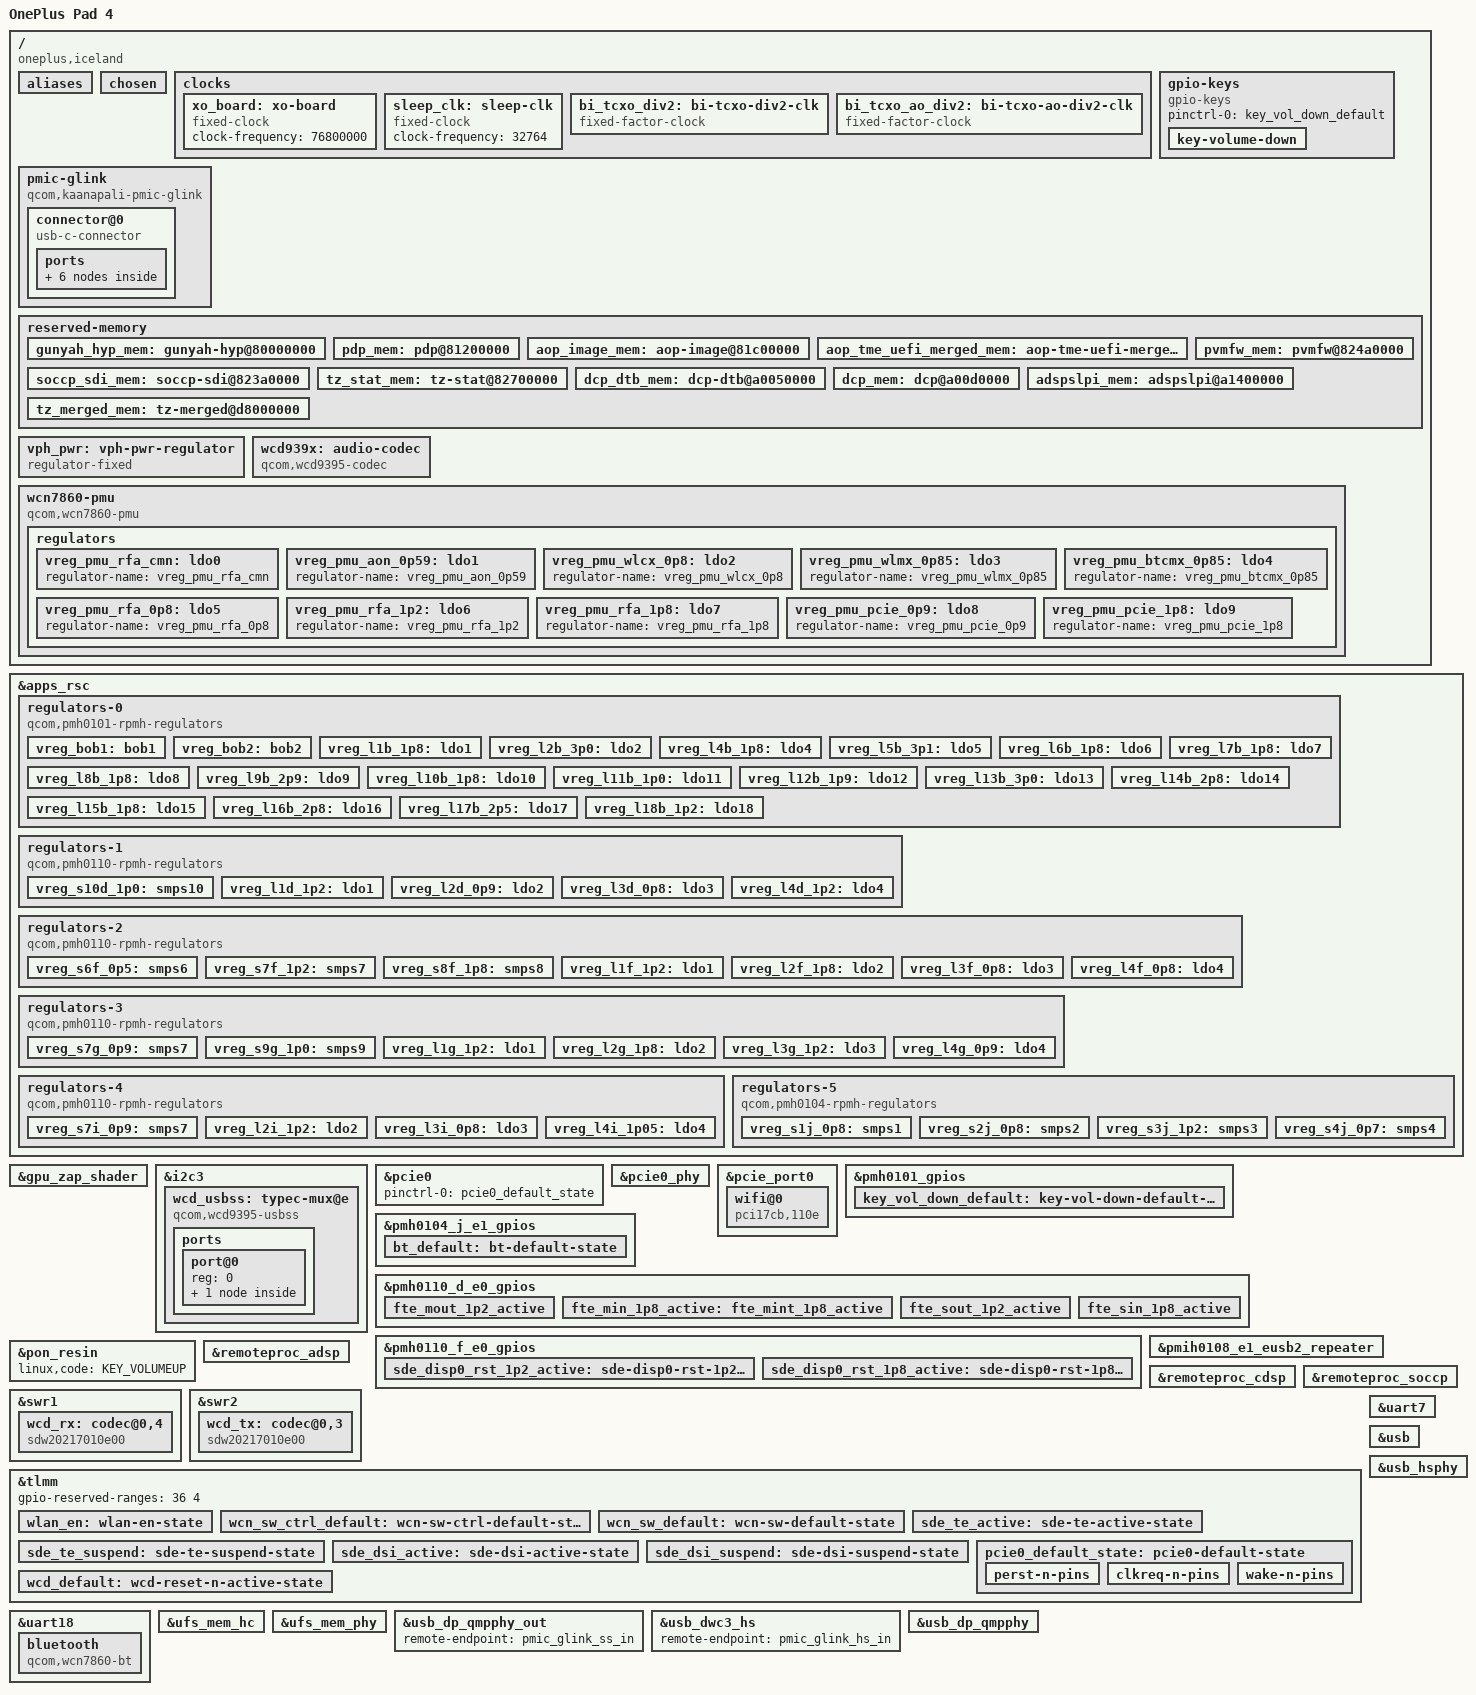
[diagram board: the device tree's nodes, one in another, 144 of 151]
// SPDX-License-Identifier: BSD-3-Clause
/*
 * Copyright (c) 2026, map220v <map220v300@gmail.com>
 */

/dts-v1/;

#include <dt-bindings/gpio/gpio.h>
#include <dt-bindings/input/linux-event-codes.h>
#include <dt-bindings/leds/common.h>
#include <dt-bindings/regulator/qcom,rpmh-regulator.h>
#include "kaanapali.dtsi"

#include "pmh0101.dtsi"              /* SPMI0: SID-1       */
#include "pmh0104-kaanapali.dtsi"    /* SPMI1: SID-9       */
#include "pmh0110-kaanapali.dtsi"    /* SPMI0: SID-3/5/6/8 */
#include "pmih0108-kaanapali.dtsi"   /* SPMI1: SID-7       */
#include "pmk8850.dtsi"              /* SPMI0: SID-0       */

/delete-node/ &pdp_mem;
/delete-node/ &adspslpi_mem;

/* SM8850P doesn't have Modem DSP */
/delete-node/ &dsm_partition_1_mem;
/delete-node/ &dsm_partition_2_mem;
/delete-node/ &mpss_mem;
/delete-node/ &q6_mpss_dtb_mem;
/delete-node/ &rmtfs_mem;

/ {
	model = "OnePlus Pad 4";
	compatible = "oneplus,iceland", "qcom,kaanapali";
	chassis-type = "tablet";

	aliases {
		serial0 = &uart7;
		serial1 = &uart18;
	};

	chosen { };

	clocks {
		xo_board: xo-board {
			compatible = "fixed-clock";
			clock-frequency = <76800000>;
			#clock-cells = <0>;
		};

		sleep_clk: sleep-clk {
			compatible = "fixed-clock";
			clock-frequency = <32764>;
			#clock-cells = <0>;
		};

		bi_tcxo_div2: bi-tcxo-div2-clk {
			compatible = "fixed-factor-clock";
			#clock-cells = <0>;

			clocks = <&rpmhcc RPMH_CXO_CLK>;
			clock-mult = <1>;
			clock-div = <2>;
		};

		bi_tcxo_ao_div2: bi-tcxo-ao-div2-clk {
			compatible = "fixed-factor-clock";
			#clock-cells = <0>;

			clocks = <&rpmhcc RPMH_CXO_CLK_A>;
			clock-mult = <1>;
			clock-div = <2>;
		};
	};

	gpio-keys {
		compatible = "gpio-keys";

		pinctrl-0 = <&key_vol_down_default>;
		pinctrl-names = "default";

		key-volume-down {
			label = "Volume Down";
			linux,code = <KEY_VOLUMEDOWN>;
			gpios = <&pmh0101_gpios 6 GPIO_ACTIVE_LOW>;
			debounce-interval = <32>;
			linux,can-disable;
			wakeup-source;
		};
	};

	pmic-glink {
		compatible = "qcom,kaanapali-pmic-glink";
		#address-cells = <1>;
		#size-cells = <0>;

		connector@0 {
			compatible = "usb-c-connector";
			reg = <0>;

			power-role = "dual";
			data-role = "dual";

			ports {
				#address-cells = <1>;
				#size-cells = <0>;

				port@0 {
					reg = <0>;

					pmic_glink_hs_in: endpoint {
						remote-endpoint = <&usb_dwc3_hs>;
					};
				};

				port@1 {
					reg = <1>;

					pmic_glink_ss_in: endpoint {
						remote-endpoint = <&usb_dp_qmpphy_out>;
					};
				};

				port@2 {
					reg = <2>;

					pmic_glink_sbu: endpoint {
						remote-endpoint = <&wcd_usbss_sbu_mux>;
					};
				};
			};
		};
	};

	reserved-memory {
		gunyah_hyp_mem: gunyah-hyp@80000000 {
			reg = <0x0 0x80000000 0x0 0xe00000>;
			no-map;
		};

		pdp_mem: pdp@81200000 {
			reg = <0x0 0x81200000 0x0 0x200000>;
			no-map;
		};

		aop_image_mem: aop-image@81c00000 {
			reg = <0x0 0x81c00000 0x0 0x60000>;
			no-map;
		};

		/* Merged aop_config, tme_crash_dump, tme_log and uefi_log regions */
		aop_tme_uefi_merged_mem: aop-tme-uefi-merged@81c80000 {
			reg = <0x0 0x81c80000 0x0 0x74000>;
			no-map;
		};

		soccp_sdi_mem: soccp-sdi@823a0000 {
			reg = <0x0 0x823a0000 0x0 0x40000>;
			no-map;
		};

		pvmfw_mem: pvmfw@824a0000 {
			reg = <0x0 0x824a0000 0x0 0x100000>;
			no-map;
		};

		tz_stat_mem: tz-stat@82700000 {
			reg = <0x0 0x82700000 0x0 0x100000>;
			no-map;
		};

		dcp_dtb_mem: dcp-dtb@a0050000 {
			reg = <0x0 0xa0050000 0x0 0x80000>;
			no-map;
		};

		dcp_mem: dcp@a00d0000 {
			reg = <0x0 0xa00d0000 0x0 0x300000>;
			no-map;
		};

		adspslpi_mem: adspslpi@a1400000 {
			reg = <0x0 0xa1400000 0x0 0x5000000>;
			no-map;
		};

		/* Merged hyp_ac, tz_reserved, xbl_sc, tz_ac, and qtee regions */
		tz_merged_mem: tz-merged@d8000000 {
			reg = <0x0 0xd8000000 0x0 0x800000>;
			no-map;
		};
	};

	vph_pwr: vph-pwr-regulator {
		compatible = "regulator-fixed";

		regulator-name = "vph_pwr";
		regulator-min-microvolt = <3700000>;
		regulator-max-microvolt = <3700000>;

		regulator-always-on;
		regulator-boot-on;
	};

	wcd939x: audio-codec {
		compatible = "qcom,wcd9395-codec", "qcom,wcd9390-codec";

		pinctrl-0 = <&wcd_default>;
		pinctrl-names = "default";

		qcom,micbias1-microvolt = <2700000>;
		qcom,micbias2-microvolt = <1800000>;
		qcom,micbias3-microvolt = <1800000>;
		qcom,micbias4-microvolt = <1800000>;
		qcom,mbhc-buttons-vthreshold-microvolt = <75000 150000 237000 500000
							  500000 500000 500000 500000>;
		qcom,mbhc-headset-vthreshold-microvolt = <1700000>;
		qcom,mbhc-headphone-vthreshold-microvolt = <50000>;
		qcom,rx-device = <&wcd_rx>;
		qcom,tx-device = <&wcd_tx>;

		reset-gpios = <&tlmm 161 GPIO_ACTIVE_LOW>;

		vdd-buck-supply = <&vreg_l15b_1p8>;
		vdd-rxtx-supply = <&vreg_l15b_1p8>;
		vdd-io-supply = <&vreg_l15b_1p8>;
		vdd-mic-bias-supply = <&vreg_bob1>;
		vdd-px-supply = <&vreg_l1g_1p2>;

		#sound-dai-cells = <1>;
	};

	wcn7860-pmu {
		compatible = "qcom,wcn7860-pmu";

		pinctrl-names = "default";
		pinctrl-0 = <&wlan_en>, <&bt_default>;

		wlan-enable-gpios = <&tlmm 16 GPIO_ACTIVE_HIGH>;
		bt-enable-gpios = <&pmh0104_j_e1_gpios 5 GPIO_ACTIVE_HIGH>;

		vddio-supply = <&vreg_l2g_1p8>;
		vddio1p2-supply = <&vreg_l3g_1p2>;
		vddaon-supply = <&vreg_s1j_0p8>;
		vdddig-supply = <&vreg_s2j_0p8>;
		vddrfa1p2-supply = <&vreg_s7f_1p2>;
		vddrfa1p8-supply = <&vreg_s8f_1p8>;

		clocks = <&rpmhcc RPMH_RF_CLK1>;

		regulators {
			vreg_pmu_rfa_cmn: ldo0 {
				regulator-name = "vreg_pmu_rfa_cmn";
			};

			vreg_pmu_aon_0p59: ldo1 {
				regulator-name = "vreg_pmu_aon_0p59";
			};

			vreg_pmu_wlcx_0p8: ldo2 {
				regulator-name = "vreg_pmu_wlcx_0p8";
			};

			vreg_pmu_wlmx_0p85: ldo3 {
				regulator-name = "vreg_pmu_wlmx_0p85";
			};

			vreg_pmu_btcmx_0p85: ldo4 {
				regulator-name = "vreg_pmu_btcmx_0p85";
			};

			vreg_pmu_rfa_0p8: ldo5 {
				regulator-name = "vreg_pmu_rfa_0p8";
			};

			vreg_pmu_rfa_1p2: ldo6 {
				regulator-name = "vreg_pmu_rfa_1p2";
			};

			vreg_pmu_rfa_1p8: ldo7 {
				regulator-name = "vreg_pmu_rfa_1p8";
			};

			vreg_pmu_pcie_0p9: ldo8 {
				regulator-name = "vreg_pmu_pcie_0p9";
			};

			vreg_pmu_pcie_1p8: ldo9 {
				regulator-name = "vreg_pmu_pcie_1p8";
			};
		};
	};
};

&apps_rsc {
	regulators-0 {
		compatible = "qcom,pmh0101-rpmh-regulators";
		qcom,pmic-id = "B_E0";

		vdd-bob1-supply = <&vph_pwr>;
		vdd-bob2-supply = <&vph_pwr>;
		vdd-l1-l4-l10-supply = <&vreg_s8f_1p8>;
		vdd-l2-l13-l14-supply = <&vreg_bob1>;
		vdd-l3-l11-supply = <&vreg_s7f_1p2>;
		vdd-l5-l16-supply = <&vreg_bob1>;
		vdd-l6-l7-supply = <&vreg_bob1>;
		vdd-l8-l9-supply = <&vreg_bob1>;
		vdd-l12-supply = <&vreg_s8f_1p8>;
		vdd-l15-supply = <&vreg_s8f_1p8>;
		vdd-l17-supply = <&vreg_bob2>;
		vdd-l18-supply = <&vreg_s7f_1p2>;

		vreg_bob1: bob1 {
			regulator-name = "vreg_bob1";
			regulator-min-microvolt = <3008000>;
			regulator-max-microvolt = <4000000>;
			regulator-initial-mode = <RPMH_REGULATOR_MODE_HPM>;
		};

		vreg_bob2: bob2 {
			regulator-name = "vreg_bob2";
			regulator-min-microvolt = <2704000>;
			regulator-max-microvolt = <3552000>;
			regulator-initial-mode = <RPMH_REGULATOR_MODE_HPM>;
		};

		vreg_l1b_1p8: ldo1 {
			regulator-name = "vreg_l1b_1p8";
			regulator-min-microvolt = <1800000>;
			regulator-max-microvolt = <1800000>;
			regulator-initial-mode = <RPMH_REGULATOR_MODE_AUTO>;
			regulator-allow-set-load;
			regulator-allowed-modes = <RPMH_REGULATOR_MODE_LPM
						   RPMH_REGULATOR_MODE_AUTO>;
		};

		vreg_l2b_3p0: ldo2 {
			regulator-name = "vreg_l2b_3p0";
			regulator-min-microvolt = <3008000>;
			regulator-max-microvolt = <3048000>;
			regulator-initial-mode = <RPMH_REGULATOR_MODE_AUTO>;
			regulator-allow-set-load;
			regulator-allowed-modes = <RPMH_REGULATOR_MODE_LPM
						   RPMH_REGULATOR_MODE_AUTO>;
		};

		vreg_l4b_1p8: ldo4 {
			regulator-name = "vreg_l4b_1p8";
			regulator-min-microvolt = <1800000>;
			regulator-max-microvolt = <1800000>;
			regulator-initial-mode = <RPMH_REGULATOR_MODE_AUTO>;
			regulator-allow-set-load;
			regulator-allowed-modes = <RPMH_REGULATOR_MODE_LPM
						   RPMH_REGULATOR_MODE_AUTO>;
		};

		vreg_l5b_3p1: ldo5 {
			regulator-name = "vreg_l5b_3p1";
			regulator-min-microvolt = <3100000>;
			regulator-max-microvolt = <3148000>;
			regulator-initial-mode = <RPMH_REGULATOR_MODE_AUTO>;
			regulator-allow-set-load;
			regulator-allowed-modes = <RPMH_REGULATOR_MODE_LPM
						   RPMH_REGULATOR_MODE_AUTO>;
		};

		vreg_l6b_1p8: ldo6 {
			regulator-name = "vreg_l6b_1p8";
			regulator-min-microvolt = <1800000>;
			regulator-max-microvolt = <3008000>;
			regulator-initial-mode = <RPMH_REGULATOR_MODE_AUTO>;
			regulator-allow-set-load;
			regulator-allowed-modes = <RPMH_REGULATOR_MODE_LPM
						   RPMH_REGULATOR_MODE_AUTO>;
		};

		vreg_l7b_1p8: ldo7 {
			regulator-name = "vreg_l7b_1p8";
			regulator-min-microvolt = <1800000>;
			regulator-max-microvolt = <3008000>;
			regulator-initial-mode = <RPMH_REGULATOR_MODE_AUTO>;
			regulator-allow-set-load;
			regulator-allowed-modes = <RPMH_REGULATOR_MODE_LPM
						   RPMH_REGULATOR_MODE_AUTO>;
		};

		vreg_l8b_1p8: ldo8 {
			regulator-name = "vreg_l8b_1p8";
			regulator-min-microvolt = <1800000>;
			regulator-max-microvolt = <3008000>;
			regulator-initial-mode = <RPMH_REGULATOR_MODE_AUTO>;
			regulator-allow-set-load;
			regulator-allowed-modes = <RPMH_REGULATOR_MODE_LPM
						   RPMH_REGULATOR_MODE_AUTO>;
		};

		vreg_l9b_2p9: ldo9 {
			regulator-name = "vreg_l9b_2p9";
			regulator-min-microvolt = <2960000>;
			regulator-max-microvolt = <3008000>;
			regulator-initial-mode = <RPMH_REGULATOR_MODE_HPM>;
			regulator-allow-set-load;
			regulator-allowed-modes = <RPMH_REGULATOR_MODE_LPM
						   RPMH_REGULATOR_MODE_HPM>;
		};

		vreg_l10b_1p8: ldo10 {
			regulator-name = "vreg_l10b_1p8";
			regulator-min-microvolt = <1800000>;
			regulator-max-microvolt = <1800000>;
			regulator-initial-mode = <RPMH_REGULATOR_MODE_AUTO>;
			regulator-allow-set-load;
			regulator-allowed-modes = <RPMH_REGULATOR_MODE_LPM
						   RPMH_REGULATOR_MODE_AUTO>;
		};

		vreg_l11b_1p0: ldo11 {
			regulator-name = "vreg_l11b_1p0";
			regulator-min-microvolt = <1000000>;
			regulator-max-microvolt = <1292000>;
			regulator-initial-mode = <RPMH_REGULATOR_MODE_AUTO>;
			regulator-allow-set-load;
			regulator-allowed-modes = <RPMH_REGULATOR_MODE_LPM
						   RPMH_REGULATOR_MODE_AUTO>;
		};

		/* OEM change for Display */
		vreg_l12b_1p9: ldo12 {
			regulator-name = "vreg_l12b_1p9";
			regulator-min-microvolt = <1800000>;//OEM set to 1.2V, but it was too low
			regulator-max-microvolt = <1896000>;
			regulator-initial-mode = <RPMH_REGULATOR_MODE_AUTO>;
			regulator-allow-set-load;
			regulator-allowed-modes = <RPMH_REGULATOR_MODE_LPM
						   RPMH_REGULATOR_MODE_AUTO>;
		};

		vreg_l13b_3p0: ldo13 {
			regulator-name = "vreg_l13b_3p0";
			regulator-min-microvolt = <3000000>;
			regulator-max-microvolt = <3000000>;
			regulator-initial-mode = <RPMH_REGULATOR_MODE_AUTO>;
			regulator-allow-set-load;
			regulator-allowed-modes = <RPMH_REGULATOR_MODE_LPM
						   RPMH_REGULATOR_MODE_AUTO>;
		};

		/* OEM change for Camera */
		vreg_l14b_2p8: ldo14 {
			regulator-name = "vreg_l14b_2p8";
			regulator-min-microvolt = <2800000>;
			regulator-max-microvolt = <2800000>;
			regulator-initial-mode = <RPMH_REGULATOR_MODE_AUTO>;
			regulator-allow-set-load;
			regulator-allowed-modes = <RPMH_REGULATOR_MODE_LPM
						   RPMH_REGULATOR_MODE_AUTO>;
		};

		vreg_l15b_1p8: ldo15 {
			regulator-name = "vreg_l15b_1p8";
			regulator-min-microvolt = <1800000>;
			regulator-max-microvolt = <1800000>;
			regulator-initial-mode = <RPMH_REGULATOR_MODE_AUTO>;
			regulator-allow-set-load;
			regulator-allowed-modes = <RPMH_REGULATOR_MODE_LPM
						   RPMH_REGULATOR_MODE_AUTO>;
		};

		/* OEM change for Camera */
		vreg_l16b_2p8: ldo16 {
			regulator-name = "vreg_l16b_2p8";
			regulator-min-microvolt = <2800000>;
			regulator-max-microvolt = <2800000>;
			regulator-initial-mode = <RPMH_REGULATOR_MODE_AUTO>;
			regulator-allow-set-load;
			regulator-allowed-modes = <RPMH_REGULATOR_MODE_LPM
						   RPMH_REGULATOR_MODE_AUTO>;
		};

		vreg_l17b_2p5: ldo17 {
			regulator-name = "vreg_l17b_2p5";
			regulator-min-microvolt = <2504000>;
			regulator-max-microvolt = <2504000>;
			regulator-initial-mode = <RPMH_REGULATOR_MODE_HPM>;
			regulator-allow-set-load;
			regulator-allowed-modes = <RPMH_REGULATOR_MODE_LPM
						   RPMH_REGULATOR_MODE_HPM>;
		};

		vreg_l18b_1p2: ldo18 {
			regulator-name = "vreg_l18b_1p2";
			regulator-min-microvolt = <1200000>;
			regulator-max-microvolt = <1200000>;
			regulator-initial-mode = <RPMH_REGULATOR_MODE_AUTO>;
			regulator-allow-set-load;
			regulator-allowed-modes = <RPMH_REGULATOR_MODE_LPM
						   RPMH_REGULATOR_MODE_AUTO>;
		};
	};

	regulators-1 {
		compatible = "qcom,pmh0110-rpmh-regulators";
		qcom,pmic-id = "D_E0";

		vdd-l1-supply = <&vreg_s7f_1p2>;
		vdd-l2-supply = <&vreg_s7g_0p9>;
		vdd-l3-supply = <&vreg_s7g_0p9>;
		vdd-l4-supply = <&vreg_s7f_1p2>;
		vdd-s10-supply = <&vph_pwr>;

		vreg_s10d_1p0: smps10 {
			regulator-name = "vreg_s10d_1p0";
			regulator-min-microvolt = <1000000>;
			regulator-max-microvolt = <1100000>;
			regulator-initial-mode = <RPMH_REGULATOR_MODE_HPM>;
		};

		vreg_l1d_1p2: ldo1 {
			regulator-name = "vreg_l1d_1p2";
			regulator-min-microvolt = <1200000>;
			regulator-max-microvolt = <1256000>;
			regulator-initial-mode = <RPMH_REGULATOR_MODE_AUTO>;
			regulator-allow-set-load;
			regulator-allowed-modes = <RPMH_REGULATOR_MODE_LPM
						   RPMH_REGULATOR_MODE_AUTO>;
		};

		vreg_l2d_0p9: ldo2 {
			regulator-name = "vreg_l2d_0p9";
			regulator-min-microvolt = <912000>;
			regulator-max-microvolt = <958000>;
			regulator-initial-mode = <RPMH_REGULATOR_MODE_AUTO>;
			regulator-allow-set-load;
			regulator-allowed-modes = <RPMH_REGULATOR_MODE_LPM
						   RPMH_REGULATOR_MODE_AUTO>;
		};

		vreg_l3d_0p8: ldo3 {
			regulator-name = "vreg_l3d_0p8";
			regulator-min-microvolt = <880000>;
			regulator-max-microvolt = <880000>;
			regulator-initial-mode = <RPMH_REGULATOR_MODE_AUTO>;
			regulator-allow-set-load;
			regulator-allowed-modes = <RPMH_REGULATOR_MODE_LPM
						   RPMH_REGULATOR_MODE_AUTO>;
		};

		vreg_l4d_1p2: ldo4 {
			regulator-name = "vreg_l4d_1p2";
			regulator-min-microvolt = <1200000>;
			regulator-max-microvolt = <1200000>;
			regulator-initial-mode = <RPMH_REGULATOR_MODE_AUTO>;
			regulator-allow-set-load;
			regulator-allowed-modes = <RPMH_REGULATOR_MODE_LPM
						   RPMH_REGULATOR_MODE_AUTO>;
		};
	};

	regulators-2 {
		compatible = "qcom,pmh0110-rpmh-regulators";
		qcom,pmic-id = "F_E0";

		vdd-l1-supply = <&vreg_s7f_1p2>;
		vdd-l2-supply = <&vreg_s8f_1p8>;
		vdd-l3-supply = <&vreg_s7g_0p9>;
		vdd-l4-supply = <&vreg_s7g_0p9>;
		vdd-s6-supply = <&vph_pwr>;
		vdd-s7-supply = <&vph_pwr>;
		vdd-s8-supply = <&vph_pwr>;

		vreg_s6f_0p5: smps6 {
			regulator-name = "vreg_s6f_0p5";
			regulator-min-microvolt = <300000>;
			regulator-max-microvolt = <570000>;
			regulator-initial-mode = <RPMH_REGULATOR_MODE_HPM>;
		};

		vreg_s7f_1p2: smps7 {
			regulator-name = "vreg_s7f_1p2";
			regulator-min-microvolt = <1224000>;
			regulator-max-microvolt = <1372000>;
			regulator-initial-mode = <RPMH_REGULATOR_MODE_HPM>;
		};

		vreg_s8f_1p8: smps8 {
			regulator-name = "vreg_s8f_1p8";
			regulator-min-microvolt = <1800000>;
			regulator-max-microvolt = <2000000>;
			regulator-initial-mode = <RPMH_REGULATOR_MODE_HPM>;
		};

		vreg_l1f_1p2: ldo1 {
			regulator-name = "vreg_l1f_1p2";
			regulator-min-microvolt = <1200000>;
			regulator-max-microvolt = <1200000>;
			regulator-initial-mode = <RPMH_REGULATOR_MODE_AUTO>;
			regulator-allow-set-load;
			regulator-allowed-modes = <RPMH_REGULATOR_MODE_LPM
						   RPMH_REGULATOR_MODE_AUTO>;
		};

		/* OEM change for Camera */
		vreg_l2f_1p8: ldo2 {
			regulator-name = "vreg_l2f_1p8";
			regulator-min-microvolt = <1800000>;
			regulator-max-microvolt = <1800000>;
			regulator-initial-mode = <RPMH_REGULATOR_MODE_AUTO>;
			regulator-allow-set-load;
			regulator-allowed-modes = <RPMH_REGULATOR_MODE_LPM
						   RPMH_REGULATOR_MODE_AUTO>;
		};

		vreg_l3f_0p8: ldo3 {
			regulator-name = "vreg_l3f_0p8";
			regulator-min-microvolt = <880000>;
			regulator-max-microvolt = <936000>;
			regulator-initial-mode = <RPMH_REGULATOR_MODE_AUTO>;
			regulator-allow-set-load;
			regulator-allowed-modes = <RPMH_REGULATOR_MODE_LPM
						   RPMH_REGULATOR_MODE_AUTO>;
		};

		vreg_l4f_0p8: ldo4 {
			regulator-name = "vreg_l4f_0p8";
			regulator-min-microvolt = <880000>;
			regulator-max-microvolt = <912000>;
			regulator-initial-mode = <RPMH_REGULATOR_MODE_AUTO>;
			regulator-allow-set-load;
			regulator-allowed-modes = <RPMH_REGULATOR_MODE_LPM
						   RPMH_REGULATOR_MODE_AUTO>;
		};
	};

	regulators-3 {
		compatible = "qcom,pmh0110-rpmh-regulators";
		qcom,pmic-id = "G_E0";

		vdd-l1-supply = <&vreg_s7f_1p2>;
		vdd-l2-supply = <&vreg_s8f_1p8>;
		vdd-l3-supply = <&vreg_s7f_1p2>;
		vdd-l4-supply = <&vreg_s7g_0p9>;
		vdd-s7-supply = <&vph_pwr>;
		vdd-s9-supply = <&vph_pwr>;

		/* OEM change */
		vreg_s7g_0p9: smps7 {
			regulator-name = "vreg_s7g_0p9";
			regulator-min-microvolt = <800000>;
			regulator-max-microvolt = <1100000>;
			regulator-initial-mode = <RPMH_REGULATOR_MODE_HPM>;
		};

		vreg_s9g_1p0: smps9 {
			regulator-name = "vreg_s9g_1p0";
			regulator-min-microvolt = <1000000>;
			regulator-max-microvolt = <1100000>;
			regulator-initial-mode = <RPMH_REGULATOR_MODE_HPM>;
		};

		vreg_l1g_1p2: ldo1 {
			regulator-name = "vreg_l1g_1p2";
			regulator-min-microvolt = <1200000>;
			regulator-max-microvolt = <1200000>;
			regulator-initial-mode = <RPMH_REGULATOR_MODE_AUTO>;
			regulator-allow-set-load;
			regulator-allowed-modes = <RPMH_REGULATOR_MODE_LPM
						   RPMH_REGULATOR_MODE_AUTO>;
		};

		vreg_l2g_1p8: ldo2 {
			regulator-name = "vreg_l2g_1p8";
			regulator-min-microvolt = <1800000>;
			regulator-max-microvolt = <1800000>;
			regulator-initial-mode = <RPMH_REGULATOR_MODE_AUTO>;
			regulator-allow-set-load;
			regulator-allowed-modes = <RPMH_REGULATOR_MODE_LPM
						   RPMH_REGULATOR_MODE_AUTO>;
		};

		vreg_l3g_1p2: ldo3 {
			regulator-name = "vreg_l3g_1p2";
			regulator-min-microvolt = <1200000>;
			regulator-max-microvolt = <1200000>;
			regulator-initial-mode = <RPMH_REGULATOR_MODE_AUTO>;
			regulator-allow-set-load;
			regulator-allowed-modes = <RPMH_REGULATOR_MODE_LPM
						   RPMH_REGULATOR_MODE_AUTO>;
		};

		vreg_l4g_0p9: ldo4 {
			regulator-name = "vreg_l4g_0p9";
			regulator-min-microvolt = <880000>;
			regulator-max-microvolt = <920000>;
			regulator-initial-mode = <RPMH_REGULATOR_MODE_AUTO>;
			regulator-allow-set-load;
			regulator-allowed-modes = <RPMH_REGULATOR_MODE_LPM
						   RPMH_REGULATOR_MODE_AUTO>;
		};
	};

	regulators-4 {
		compatible = "qcom,pmh0110-rpmh-regulators";
		qcom,pmic-id = "I_E0";

		vdd-l2-supply = <&vreg_s7f_1p2>;
		vdd-l3-supply = <&vreg_s7g_0p9>;
		vdd-l4-supply = <&vreg_s7f_1p2>;
		vdd-s7-supply = <&vph_pwr>;

		vreg_s7i_0p9: smps7 {
			regulator-name = "vreg_s7i_0p9";
			regulator-min-microvolt = <900000>;
			regulator-max-microvolt = <972000>;
			regulator-initial-mode = <RPMH_REGULATOR_MODE_HPM>;
		};

		vreg_l2i_1p2: ldo2 {
			regulator-name = "vreg_l2i_1p2";
			regulator-min-microvolt = <1200000>;
			regulator-max-microvolt = <1200000>;
			regulator-initial-mode = <RPMH_REGULATOR_MODE_AUTO>;
			regulator-allow-set-load;
			regulator-allowed-modes = <RPMH_REGULATOR_MODE_LPM
						   RPMH_REGULATOR_MODE_AUTO>;
		};

		vreg_l3i_0p8: ldo3 {
			regulator-name = "vreg_l3i_0p8";
			regulator-min-microvolt = <880000>;
			regulator-max-microvolt = <920000>;
			regulator-initial-mode = <RPMH_REGULATOR_MODE_AUTO>;
			regulator-allow-set-load;
			regulator-allowed-modes = <RPMH_REGULATOR_MODE_LPM
						   RPMH_REGULATOR_MODE_AUTO>;
		};

		/* OEM change(unused?) */
		vreg_l4i_1p05: ldo4 {
			regulator-name = "vreg_l4i_1p05";
			regulator-min-microvolt = <1048000>;
			regulator-max-microvolt = <1048000>;
			regulator-initial-mode = <RPMH_REGULATOR_MODE_AUTO>;
			regulator-allow-set-load;
			regulator-allowed-modes = <RPMH_REGULATOR_MODE_LPM
						   RPMH_REGULATOR_MODE_AUTO>;
		};
	};

	regulators-5 {
		compatible = "qcom,pmh0104-rpmh-regulators";
		qcom,pmic-id = "J_E1";

		vdd-s1-supply = <&vph_pwr>;
		vdd-s2-supply = <&vph_pwr>;
		vdd-s3-supply = <&vph_pwr>;
		vdd-s4-supply = <&vph_pwr>;

		vreg_s1j_0p8: smps1 {
			regulator-name = "vreg_s1j_0p8";
			regulator-min-microvolt = <400000>;
			regulator-max-microvolt = <1000000>;
			regulator-initial-mode = <RPMH_REGULATOR_MODE_HPM>;
		};

		vreg_s2j_0p8: smps2 {
			regulator-name = "vreg_s2j_0p8";
			regulator-min-microvolt = <500000>;
			regulator-max-microvolt = <1100000>;
			regulator-initial-mode = <RPMH_REGULATOR_MODE_HPM>;
		};

		vreg_s3j_1p2: smps3 {
			regulator-name = "vreg_s3j_1p2";
			regulator-min-microvolt = <1200000>;
			regulator-max-microvolt = <1300000>;
			regulator-initial-mode = <RPMH_REGULATOR_MODE_HPM>;
		};

		vreg_s4j_0p7: smps4 {
			regulator-name = "vreg_s4j_0p7";
			regulator-min-microvolt = <300000>;
			regulator-max-microvolt = <1000000>;
			regulator-initial-mode = <RPMH_REGULATOR_MODE_HPM>;
		};
	};
};

&gpu_zap_shader {
	firmware-name = "qcom/kaanapali/iceland/gen80200_zap.mbn";
};

&i2c3 {
	status = "okay";

	wcd_usbss: typec-mux@e {
		compatible = "qcom,wcd9395-usbss", "qcom,wcd9390-usbss";
		reg = <0xe>;

		vdd-supply = <&vreg_l15b_1p8>;
		reset-gpios = <&tlmm 162 GPIO_ACTIVE_HIGH>;

		mode-switch;
		orientation-switch;

		ports {
			#address-cells = <1>;
			#size-cells = <0>;

			port@0 {
				reg = <0>;

				wcd_usbss_sbu_mux: endpoint {
					remote-endpoint = <&pmic_glink_sbu>;
				};
			};
		};
	};
};

&pcie0 {
	pinctrl-0 = <&pcie0_default_state>;
	pinctrl-names = "default";

	status = "okay";
};

&pcie0_phy {
	vdda-phy-supply = <&vreg_l3i_0p8>;
	vdda-pll-supply = <&vreg_l1d_1p2>;

	status = "okay";
};

&pcie_port0 {
	wake-gpios = <&tlmm 104 GPIO_ACTIVE_HIGH>;
	reset-gpios = <&tlmm 102 GPIO_ACTIVE_LOW>;

	wifi@0 {
		compatible = "pci17cb,110e";
		reg = <0x10000 0x0 0x0 0x0 0x0>;

		vddrfacmn-supply = <&vreg_pmu_rfa_cmn>;
		vddaon-supply = <&vreg_pmu_aon_0p59>;
		vddwlcx-supply = <&vreg_pmu_wlcx_0p8>;
		vddwlmx-supply = <&vreg_pmu_wlmx_0p85>;
		vddrfa0p8-supply = <&vreg_pmu_rfa_0p8>;
		vddrfa1p2-supply = <&vreg_pmu_rfa_1p2>;
		vddrfa1p8-supply = <&vreg_pmu_rfa_1p8>;
		vddpcie0p9-supply = <&vreg_pmu_pcie_0p9>;
		vddpcie1p8-supply = <&vreg_pmu_pcie_1p8>;
	};
};

&pmh0101_gpios {
	key_vol_down_default: key-vol-down-default-state {
		pins = "gpio6";
		function = "normal";
		input-enable;
		bias-pull-up;
		power-source = <1>;
	};
};

&pmh0104_j_e1_gpios {
	bt_default: bt-default-state {
		pins = "gpio5";
		function = "normal";
		input-disable;
		output-enable;
		output-low;
		bias-disable;
		power-source = <1>;
	};
};

&pmh0110_d_e0_gpios {
	fte_mout_1p2_active: fte_mout_1p2_active {
		pins = "gpio7";
		function = "paired";
		input-disable;
		output-enable;
		power-source = <2>; /* 1.2V */
	};

	fte_min_1p8_active: fte_mint_1p8_active {
		pins = "gpio8";
		function = "paired";
		input-enable;
		output-disable;
		power-source = <1>; /* 1.8V */
	};

	fte_sout_1p2_active: fte_sout_1p2_active {
		pins = "gpio9";
		function = "paired";
		input-disable;
		output-enable;
		power-source = <2>; /* 1.2V */
	};

	fte_sin_1p8_active: fte_sin_1p8_active {
		pins = "gpio10";
		function = "paired";
		input-enable;
		output-disable;
		power-source = <1>; /* 1.8V */
	};
};

&pmh0110_f_e0_gpios {
	sde_disp0_rst_1p2_active: sde-disp0-rst-1p2-active-state {
		pins = "gpio9";
		function = "paired";
		input-enable;
		output-disable;
		power-source = <2>; /* 1.2v */
	};

	sde_disp0_rst_1p8_active: sde-disp0-rst-1p8-active-state {
		pins = "gpio10";
		function = "paired";
		input-disable;
		output-enable;
		power-source = <1>; /* 1.8v */
	};
};

&pmih0108_e1_eusb2_repeater {
	vdd18-supply = <&vreg_l15b_1p8>;
	vdd3-supply = <&vreg_l5b_3p1>;
};

&pon_resin {
	linux,code = <KEY_VOLUMEUP>;

	status = "okay";
};

&remoteproc_adsp {
	firmware-name = "qcom/kaanapali/iceland/adsp.mbn",
			"qcom/kaanapali/iceland/adsp_dtb.mbn";

	status = "okay";
};

&remoteproc_cdsp {
	firmware-name = "qcom/kaanapali/iceland/cdsp.mbn",
			"qcom/kaanapali/iceland/cdsp_dtb.mbn";

	status = "okay";
};

&remoteproc_soccp {
	firmware-name = "qcom/kaanapali/iceland/soccp.mbn",
			"qcom/kaanapali/iceland/soccp_dtb.mbn";

	status = "okay";
};

&swr1 {
	status = "okay";

	/* WCD9395 RX */
	wcd_rx: codec@0,4 {
		compatible = "sdw20217010e00";
		reg = <0 4>;

		/*
		 * WCD9395 RX Port 1 (HPH_L/R)      <=> SWR1 Port 1 (HPH_L/R)
		 * WCD9395 RX Port 2 (CLSH)         <=> SWR1 Port 2 (CLSH)
		 * WCD9395 RX Port 3 (COMP_L/R)     <=> SWR1 Port 3 (COMP_L/R)
		 * WCD9395 RX Port 4 (LO)           <=> SWR1 Port 4 (LO)
		 * WCD9395 RX Port 5 (DSD_L/R)      <=> SWR1 Port 5 (DSD_L/R)
		 * WCD9395 RX Port 6 (HIFI_PCM_L/R) <=> SWR1 Port 9 (HIFI_PCM_L/R)
		 */
		qcom,rx-port-mapping = <1 2 3 4 5 9>;
	};
};

&swr2 {
	status = "okay";

	/* WCD9395 TX */
	wcd_tx: codec@0,3 {
		compatible = "sdw20217010e00";
		reg = <0 3>;

		/*
		 * WCD9395 TX Port 1 (ADC1,2,3,4)         <=> SWR2 Port 2 (TX SWR_INPUT 0,1,2,3)
		 * WCD9395 TX Port 2 (ADC3,4 & DMIC0,1)   <=> SWR2 Port 2 (TX SWR_INPUT 0,1,2,3)
		 * WCD9395 TX Port 3 (DMIC0,1,2,3 & MBHC) <=> SWR2 Port 3 (TX SWR_INPUT 4,5,6,7)
		 * WCD9395 TX Port 4 (DMIC4,5,6,7)        <=> SWR2 Port 4 (TX SWR_INPUT 8,9,10,11)
		 */
		qcom,tx-port-mapping = <2 2 3 4>;
	};
};

&tlmm {
	gpio-reserved-ranges = <36 4>;

	wlan_en: wlan-en-state {
		pins = "gpio16";
		function = "gpio";
		drive-strength = <8>;
		bias-pull-down;
	};

	wcn_sw_ctrl_default: wcn-sw-ctrl-default-state {
		pins = "gpio18";
		function = "wcn_sw_ctrl";
		bias-pull-down;
	};

	wcn_sw_default: wcn-sw-default-state {
		pins = "gpio18";
		function = "wcn_sw";
		bias-pull-down;
	};

	sde_te_active: sde-te-active-state {
		pins = "gpio86";
		function = "mdp_vsync";
		drive-strength = <2>;
		bias-pull-down;
	};

	sde_te_suspend: sde-te-suspend-state {
		pins = "gpio86";
		function = "mdp_vsync";
		drive-strength = <2>;
		bias-pull-down;
	};

	sde_dsi_active: sde-dsi-active-state {
		pins = "gpio171";
		function = "gpio";
		drive-strength = <8>;
		bias-disable;
	};

	sde_dsi_suspend: sde-dsi-suspend-state {
		pins = "gpio171";
		function = "gpio";
		drive-strength = <2>;
		bias-pull-down;
	};

	pcie0_default_state: pcie0-default-state {
		perst-n-pins {
			pins = "gpio102";
			function = "gpio";
			drive-strength = <2>;
			bias-disable;
		};

		clkreq-n-pins {
			pins = "gpio103";
			function = "pcie0_clk_req_n";
			drive-strength = <2>;
			bias-pull-up;
		};

		wake-n-pins {
			pins = "gpio104";
			function = "gpio";
			drive-strength = <2>;
			bias-pull-up;
		};
	};

	wcd_default: wcd-reset-n-active-state {
		pins = "gpio161";
		function = "gpio";
		drive-strength = <16>;
		bias-disable;
	};
};

&uart7 {
	status = "okay";
};

&uart18 {
	status = "okay";

	bluetooth {
		compatible = "qcom,wcn7860-bt";

		local-bd-address = [ 25 00 00 00 5a ad ];

		vddrfacmn-supply = <&vreg_pmu_rfa_cmn>;
		vddaon-supply = <&vreg_pmu_aon_0p59>;
		vddwlcx-supply = <&vreg_pmu_wlcx_0p8>;
		vddwlmx-supply = <&vreg_pmu_wlmx_0p85>;
		vddrfa0p8-supply = <&vreg_pmu_rfa_0p8>;
		vddrfa1p2-supply = <&vreg_pmu_rfa_1p2>;
		vddrfa1p8-supply = <&vreg_pmu_rfa_1p8>;

		max-speed = <3200000>;
	};
};

&ufs_mem_hc {
	reset-gpios = <&tlmm 217 GPIO_ACTIVE_LOW>;

	vcc-supply = <&vreg_l17b_2p5>;
	vcc-max-microamp = <1200000>;
	vccq-supply = <&vreg_l4d_1p2>;
	vccq-max-microamp = <1200000>;

	status = "okay";
};

&ufs_mem_phy {
	vdda-phy-supply = <&vreg_l4g_0p9>;
	vdda-pll-supply = <&vreg_l1d_1p2>;

	status = "okay";
};

&usb {
	status = "okay";
};

&usb_dp_qmpphy_out {
	remote-endpoint = <&pmic_glink_ss_in>;
};

&usb_dwc3_hs {
	remote-endpoint = <&pmic_glink_hs_in>;
};

&usb_hsphy {
	vdd-supply = <&vreg_l4f_0p8>;
	vdda12-supply = <&vreg_l1d_1p2>;

	phys = <&pmih0108_e1_eusb2_repeater>;

	status = "okay";
};

&usb_dp_qmpphy {
	vdda-phy-supply = <&vreg_l4f_0p8>;
	vdda-pll-supply = <&vreg_l1d_1p2>;

	status = "okay";
};
